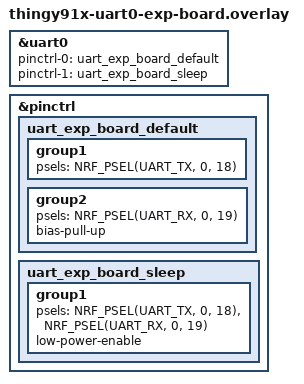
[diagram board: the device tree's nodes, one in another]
&uart0 {
	pinctrl-0 = <&uart_exp_board_default>;
	pinctrl-1 = <&uart_exp_board_sleep>;
};

&pinctrl {
	uart_exp_board_default: uart_exp_board_default {
		group1 {
			psels = <NRF_PSEL(UART_TX, 0, 18)>;
		};
		group2 {
			psels = <NRF_PSEL(UART_RX, 0, 19)>;
			bias-pull-up;
		};
	};

	uart_exp_board_sleep: uart_exp_board_sleep {
		group1 {
			psels = <NRF_PSEL(UART_TX, 0, 18)>,
				<NRF_PSEL(UART_RX, 0, 19)>;
			low-power-enable;
		};
	};
};
